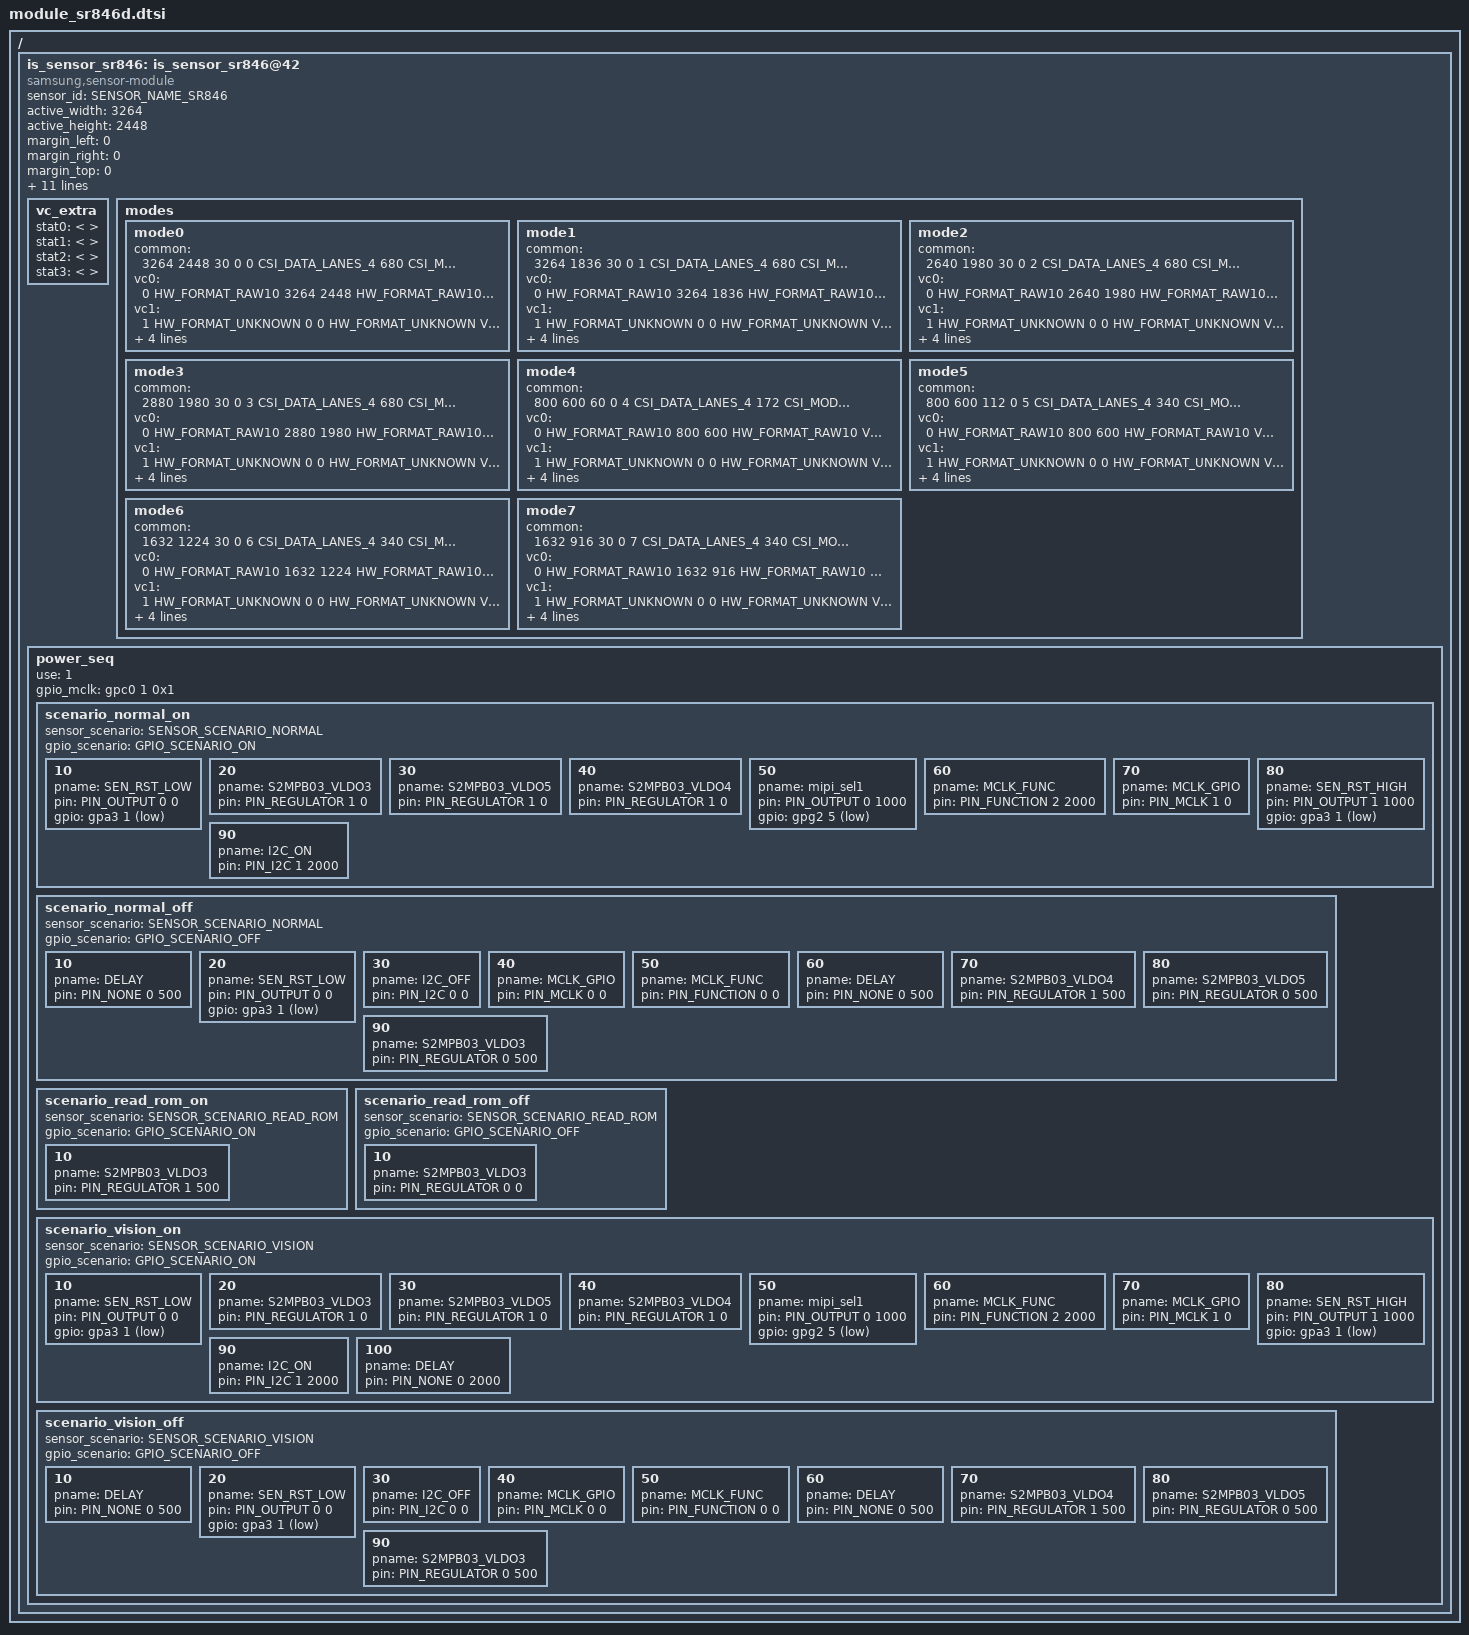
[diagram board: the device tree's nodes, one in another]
/*
 * SAMSUNG EXYNOSxxxx board camera device tree source
 *
 * Copyright (c) 2020 Samsung Electronics Co., Ltd.
 *		http://www.samsung.com
 *
 * This program is free software; you can redistribute it and/or modify
 * it under the terms of the GNU General Public License version 2 as
 * published by the Free Software Foundation.
 */

#include <dt-bindings/camera/exynos_is_dt.h>

#ifndef USE_VENDOR_PWR_PIN_NAME
#define SR846_IOVDD		<>
#define SR846_AVDD		<>
#define SR846_DVDD		<>
#endif

/ {
	fragment@camera {
		target-path = "/";
		__overlay__ {
			is_sensor_sr846: is_sensor_sr846@42 {
				compatible = "samsung,sensor-module";

				/* common */
				sensor_id = <SENSOR_NAME_SR846>;
				active_width = <3264>;
				active_height = <2448>;
				margin_left = <0>;
				margin_right = <0>;
				margin_top = <0>;
				margin_bottom = <0>;
				max_framerate = <120>;
				bitwidth = <10>;
				use_retention_mode = <SENSOR_RETENTION_UNSUPPORTED>;
				sensor_maker = "HYNIX";
				sensor_name = "SR846";
				setfile_name = "setfile_sr846.bin";
				
				sr846_iovdd-supply = SR846_IOVDD;
				sr846_avdd-supply = SR846_AVDD;
				sr846_dvdd-supply = SR846_DVDD;

				status = "okay";

				vc_extra {
					/* ex) statX = <stat_type, sensor_mode, max_width, max_height, max_element> */
					stat0 = </* not avaliable */>;	/* VC_BUF_DATA_TYPE_SENSOR_STAT1 */
					stat1 = </* not avaliable */>;	/* VC_BUF_DATA_TYPE_GENERAL_STAT1 */
					stat2 = </* not avaliable */>;	/* VC_BUF_DATA_TYPE_SENSOR_STAT2 */
					stat3 = </* not avaliable */>;	/* VC_BUF_DATA_TYPE_GENERAL_STAT2 */
				};

				/* sensor modes */
				modes {
						/* common = <width, height, fps, settle, mode, lane, speed, interleave, lrte, pd_mode> */
						/* vcX = <map, hwformat, width, height, hwformat, type, width, height> */
					mode0 {
						common = <3264 2448 30 0 0 CSI_DATA_LANES_4 680 CSI_MODE_VC_ONLY LRTE_DISABLE PD_NONE EX_NONE>;
						vc0 = </* in */ 0 HW_FORMAT_RAW10 3264 2448	/* out */ HW_FORMAT_RAW10 VC_NOTHING 0 0>;
						vc1 = </* in */ 1 HW_FORMAT_UNKNOWN 0 0		/* out */ HW_FORMAT_UNKNOWN VC_NOTHING 0 0>;
						vc2 = </* in */ 2 HW_FORMAT_UNKNOWN 0 0		/* out */ HW_FORMAT_UNKNOWN VC_NOTHING 0 0>;
						vc3 = </* in */ 3 HW_FORMAT_UNKNOWN 0 0		/* out */ HW_FORMAT_UNKNOWN VC_NOTHING 0 0>;
					};
					mode1 {
						common = <3264 1836 30 0 1 CSI_DATA_LANES_4 680 CSI_MODE_VC_ONLY LRTE_DISABLE PD_NONE EX_NONE>;
						vc0 = <0 HW_FORMAT_RAW10 3264 1836	/* out */ HW_FORMAT_RAW10 VC_NOTHING 0 0>;
						vc1 = <1 HW_FORMAT_UNKNOWN 0 0		/* out */ HW_FORMAT_UNKNOWN VC_NOTHING 0 0>;
						vc2 = <2 HW_FORMAT_UNKNOWN 0 0		/* out */ HW_FORMAT_UNKNOWN VC_NOTHING 0 0>;
						vc3 = <3 HW_FORMAT_UNKNOWN 0 0		/* out */ HW_FORMAT_UNKNOWN VC_NOTHING 0 0>;
					};
					mode2 {
						common = <2640 1980 30 0 2 CSI_DATA_LANES_4 680 CSI_MODE_VC_ONLY LRTE_DISABLE PD_NONE EX_NONE>;
						vc0 = <0 HW_FORMAT_RAW10 2640 1980	/* out */ HW_FORMAT_RAW10 VC_NOTHING 0 0>;
						vc1 = <1 HW_FORMAT_UNKNOWN 0 0		/* out */ HW_FORMAT_UNKNOWN VC_NOTHING 0 0>;
						vc2 = <2 HW_FORMAT_UNKNOWN 0 0		/* out */ HW_FORMAT_UNKNOWN VC_NOTHING 0 0>;
						vc3 = <3 HW_FORMAT_UNKNOWN 0 0		/* out */ HW_FORMAT_UNKNOWN VC_NOTHING 0 0>;
					};
					mode3 {
						common = <2880 1980 30 0 3 CSI_DATA_LANES_4 680 CSI_MODE_VC_ONLY LRTE_DISABLE PD_NONE EX_NONE>;
						vc0 = <0 HW_FORMAT_RAW10 2880 1980	/* out */ HW_FORMAT_RAW10 VC_NOTHING 0 0>;
						vc1 = <1 HW_FORMAT_UNKNOWN 0 0		/* out */ HW_FORMAT_UNKNOWN VC_NOTHING 0 0>;
						vc2 = <2 HW_FORMAT_UNKNOWN 0 0		/* out */ HW_FORMAT_UNKNOWN VC_NOTHING 0 0>;
						vc3 = <3 HW_FORMAT_UNKNOWN 0 0		/* out */ HW_FORMAT_UNKNOWN VC_NOTHING 0 0>;
					};
					mode4 {
						common = <800 600 60 0 4 CSI_DATA_LANES_4  172 CSI_MODE_VC_ONLY LRTE_DISABLE PD_NONE EX_NONE>;
						vc0 = <0 HW_FORMAT_RAW10 800 600	/* out */ HW_FORMAT_RAW10 VC_NOTHING 0 0>;
						vc1 = <1 HW_FORMAT_UNKNOWN 0 0		/* out */ HW_FORMAT_UNKNOWN VC_NOTHING 0 0>;
						vc2 = <2 HW_FORMAT_UNKNOWN 0 0		/* out */ HW_FORMAT_UNKNOWN VC_NOTHING 0 0>;
						vc3 = <3 HW_FORMAT_UNKNOWN 0 0		/* out */ HW_FORMAT_UNKNOWN VC_NOTHING 0 0>;
					};
					mode5 {
						common = <800 600 112 0 5 CSI_DATA_LANES_4  340 CSI_MODE_VC_ONLY LRTE_DISABLE PD_NONE EX_NONE>;
						vc0 = <0 HW_FORMAT_RAW10 800 600	/* out */ HW_FORMAT_RAW10 VC_NOTHING 0 0>;
						vc1 = <1 HW_FORMAT_UNKNOWN 0 0		/* out */ HW_FORMAT_UNKNOWN VC_NOTHING 0 0>;
						vc2 = <2 HW_FORMAT_UNKNOWN 0 0		/* out */ HW_FORMAT_UNKNOWN VC_NOTHING 0 0>;
						vc3 = <3 HW_FORMAT_UNKNOWN 0 0		/* out */ HW_FORMAT_UNKNOWN VC_NOTHING 0 0>;
					};
					mode6 {
						common = <1632 1224 30 0 6 CSI_DATA_LANES_4  340 CSI_MODE_VC_ONLY LRTE_DISABLE PD_NONE EX_NONE>;
						vc0 = <0 HW_FORMAT_RAW10 1632 1224	/* out */ HW_FORMAT_RAW10 VC_NOTHING 0 0>;
						vc1 = <1 HW_FORMAT_UNKNOWN 0 0		/* out */ HW_FORMAT_UNKNOWN VC_NOTHING 0 0>;
						vc2 = <2 HW_FORMAT_UNKNOWN 0 0		/* out */ HW_FORMAT_UNKNOWN VC_NOTHING 0 0>;
						vc3 = <3 HW_FORMAT_UNKNOWN 0 0		/* out */ HW_FORMAT_UNKNOWN VC_NOTHING 0 0>;
					};
					mode7 {
						common = <1632 916 30 0 7 CSI_DATA_LANES_4  340 CSI_MODE_VC_ONLY LRTE_DISABLE PD_NONE EX_NONE>;
						vc0 = <0 HW_FORMAT_RAW10 1632 916	/* out */ HW_FORMAT_RAW10 VC_NOTHING 0 0>;
						vc1 = <1 HW_FORMAT_UNKNOWN 0 0		/* out */ HW_FORMAT_UNKNOWN VC_NOTHING 0 0>;
						vc2 = <2 HW_FORMAT_UNKNOWN 0 0		/* out */ HW_FORMAT_UNKNOWN VC_NOTHING 0 0>;
						vc3 = <3 HW_FORMAT_UNKNOWN 0 0		/* out */ HW_FORMAT_UNKNOWN VC_NOTHING 0 0>;
					};
				};

				power_seq {
					use = <1>;
					gpio_mclk = <&gpc0 1 0x1>;

					scenario_normal_on {
						sensor_scenario = <SENSOR_SCENARIO_NORMAL>;
						gpio_scenario = <GPIO_SCENARIO_ON>;

						/* A start node number should be over the 10 for reserved number 0~9. */
						/* pname = "name"; pin = <act value dealy voltage>; gpio = <gpx# # 0x1>; */
						10 { pname = SEN_RST_LOW; pin = <PIN_OUTPUT 0 0>; gpio = <&gpa3 1 0x1>; };
						20 { pname = "S2MPB03_VLDO3"; pin = <PIN_REGULATOR 1 0>; }; /* CAM_VDDIO_1P8 */
						30 { pname = "S2MPB03_VLDO5"; pin = <PIN_REGULATOR 1 0>; }; /* RCAM3_AVDD_2P8 */
						40 { pname = "S2MPB03_VLDO4"; pin = <PIN_REGULATOR 1 0>; }; /* RCAM3_DVDD_1P2 */
						50 { pname = "mipi_sel1"; pin = <PIN_OUTPUT 0 1000>; gpio = <&gpg2 5 0x1>; }; /* MIPI Select 1 : RCAM3 & FRONT  */
						60 { pname = MCLK_FUNC; pin = <PIN_FUNCTION 2 2000>; };
						70 { pname = MCLK_GPIO; pin = <PIN_MCLK 1 0>; };
						80 { pname = SEN_RST_HIGH; pin = <PIN_OUTPUT 1 1000>; gpio = <&gpa3 1 0x1>; };
						90 { pname = I2C_ON; pin = <PIN_I2C 1 2000>; };
					};

					scenario_normal_off {
						sensor_scenario = <SENSOR_SCENARIO_NORMAL>;
						gpio_scenario = <GPIO_SCENARIO_OFF>;

						/* A start node number should be over the 10 for reserved number 0~9. */
						/* pname = "name"; pin = <act value dealy voltage>;	gpio = <gpx# # 0x1>; */
						10 { pname = DELAY; pin = <PIN_NONE 0 500>; };
						20 { pname = SEN_RST_LOW; pin = <PIN_OUTPUT 0 0>; gpio = <&gpa3 1 0x1>; };
						30 { pname = I2C_OFF; pin = <PIN_I2C 0 0>; };
						40 { pname = MCLK_GPIO; pin = <PIN_MCLK 0 0>; };
						50 { pname = MCLK_FUNC; pin = <PIN_FUNCTION 0 0>; };
						60 { pname = DELAY; pin = <PIN_NONE 0 500>; };
						70 { pname = "S2MPB03_VLDO4"; pin = <PIN_REGULATOR 1 500>; }; /* RCAM3_DVDD_1P2 */
						80 { pname = "S2MPB03_VLDO5"; pin = <PIN_REGULATOR 0 500>; };  /* RCAM3_AVDD_2P8 */
						90 { pname = "S2MPB03_VLDO3"; pin = <PIN_REGULATOR 0 500>; }; /* CAM_VDDIO_1P8 */
					};

					scenario_read_rom_on {
						sensor_scenario = <SENSOR_SCENARIO_READ_ROM>;
						gpio_scenario = <GPIO_SCENARIO_ON>;

						10 { pname = "S2MPB03_VLDO3"; pin = <PIN_REGULATOR 1 500>; };	/* CAM_VDDIO_1P8 */
					};

					scenario_read_rom_off {
						sensor_scenario = <SENSOR_SCENARIO_READ_ROM>;
						gpio_scenario = <GPIO_SCENARIO_OFF>;

						10 { pname = "S2MPB03_VLDO3"; pin = <PIN_REGULATOR 0 0>; };	/* CAM_VDDIO_1P8 */
					};

					scenario_vision_on {
						sensor_scenario = <SENSOR_SCENARIO_VISION>;
						gpio_scenario = <GPIO_SCENARIO_ON>;

						/* A start node number should be over the 10 for reserved number 0~9. */
						/* pname = "name"; pin = <act value dealy voltage>; gpio = <gpx# # 0x1>; */
						10 { pname = SEN_RST_LOW; pin = <PIN_OUTPUT 0 0>; gpio = <&gpa3 1 0x1>; };
						20 { pname = "S2MPB03_VLDO3"; pin = <PIN_REGULATOR 1 0>; }; /* CAM_VDDIO_1P8 */
						30 { pname = "S2MPB03_VLDO5"; pin = <PIN_REGULATOR 1 0>; }; /* RCAM3_AVDD_2P8 */
						40 { pname = "S2MPB03_VLDO4"; pin = <PIN_REGULATOR 1 0>; }; /* RCAM3_DVDD_1P2 */
						50 { pname = "mipi_sel1"; pin = <PIN_OUTPUT 0 1000>; gpio = <&gpg2 5 0x1>; }; /* MIPI Select 1 : RCAM3 & FRONT  */
						60 { pname = MCLK_FUNC; pin = <PIN_FUNCTION 2 2000>; };
						70 { pname = MCLK_GPIO; pin = <PIN_MCLK 1 0>; };
						80 { pname = SEN_RST_HIGH; pin = <PIN_OUTPUT 1 1000>; gpio = <&gpa3 1 0x1>; };
						90 { pname = I2C_ON; pin = <PIN_I2C 1 2000>; };
						100 { pname = DELAY; pin = <PIN_NONE 0 2000>; };
					};

					scenario_vision_off {
						sensor_scenario = <SENSOR_SCENARIO_VISION>;
						gpio_scenario = <GPIO_SCENARIO_OFF>;

						/* A start node number should be over the 10 for reserved number 0~9. */
						/* pname = "name"; pin = <act value dealy voltage>;	gpio = <gpx# # 0x1>; */
						10 { pname = DELAY; pin = <PIN_NONE 0 500>; };
						20 { pname = SEN_RST_LOW; pin = <PIN_OUTPUT 0 0>; gpio = <&gpa3 1 0x1>; };
						30 { pname = I2C_OFF; pin = <PIN_I2C 0 0>; };
						40 { pname = MCLK_GPIO; pin = <PIN_MCLK 0 0>; };
						50 { pname = MCLK_FUNC; pin = <PIN_FUNCTION 0 0>; };
						60 { pname = DELAY; pin = <PIN_NONE 0 500>; };
						70 { pname = "S2MPB03_VLDO4"; pin = <PIN_REGULATOR 1 500>; }; /* RCAM3_DVDD_1P2 */
						80 { pname = "S2MPB03_VLDO5"; pin = <PIN_REGULATOR 0 500>; };  /* RCAM3_AVDD_2P8 */
						90 { pname = "S2MPB03_VLDO3"; pin = <PIN_REGULATOR 0 500>; }; /* CAM_VDDIO_1P8 */
					};
				};
			};
		}; /* end of __overlay__ */
	}; /* end of fragment */
}; /* end of root */
